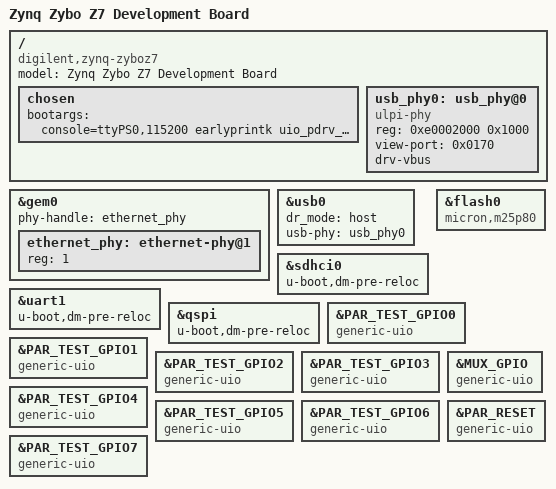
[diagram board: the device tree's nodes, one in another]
/include/ "system-conf.dtsi"
#include <dt-bindings/gpio/gpio.h>
#include <dt-bindings/media/xilinx-vip.h>

/ {
	model = "Zynq Zybo Z7 Development Board";
	compatible = "digilent,zynq-zyboz7", "xlnx,zynq-7000";

	chosen {
		bootargs = "console=ttyPS0,115200 earlyprintk uio_pdrv_genirq.of_id=generic-uio root=/dev/mmcblk0p2 rw rootwait";
	};

	usb_phy0: usb_phy@0 {
		compatible = "ulpi-phy";
		#phy-cells = <0>;
		reg = <0xe0002000 0x1000>;
		view-port = <0x0170>;
		drv-vbus;
	};


};

&gem0 {
	phy-handle = <&ethernet_phy>;
/*	phy-reset-gpio = <&axi_gpio_eth 0 0>;
	phy-reset-active-low;	
	phy-reset-duration = <10>; */
	ethernet_phy: ethernet-phy@1 { /* rtl8211e-vl */
		reg = <1>;
		device_type = "ethernet-phy";
	};
};

&usb0 {	
	dr_mode = "host";
	usb-phy = <&usb_phy0>;
};
&sdhci0 {
	u-boot,dm-pre-reloc;
};
&uart1 {
	u-boot,dm-pre-reloc;
};

&qspi {
	u-boot,dm-pre-reloc;
};
&flash0 {
	compatible = "micron,m25p80", "s25fl128s", "spi-flash";
};
&PAR_TEST_GPIO0 {
	compatible = "generic-uio";
};
&PAR_TEST_GPIO1 {
	compatible = "generic-uio";
};
&PAR_TEST_GPIO2 {
	compatible = "generic-uio";
};
&PAR_TEST_GPIO3 {
	compatible = "generic-uio";
};
&PAR_TEST_GPIO4 {
	compatible = "generic-uio";
};
&PAR_TEST_GPIO5 {
	compatible = "generic-uio";
};
&PAR_TEST_GPIO6 {
	compatible = "generic-uio";
};
&PAR_TEST_GPIO7 {
	compatible = "generic-uio";
};
&MUX_GPIO {
	compatible = "generic-uio";
};
&PAR_RESET {
	compatible = "generic-uio";
};
